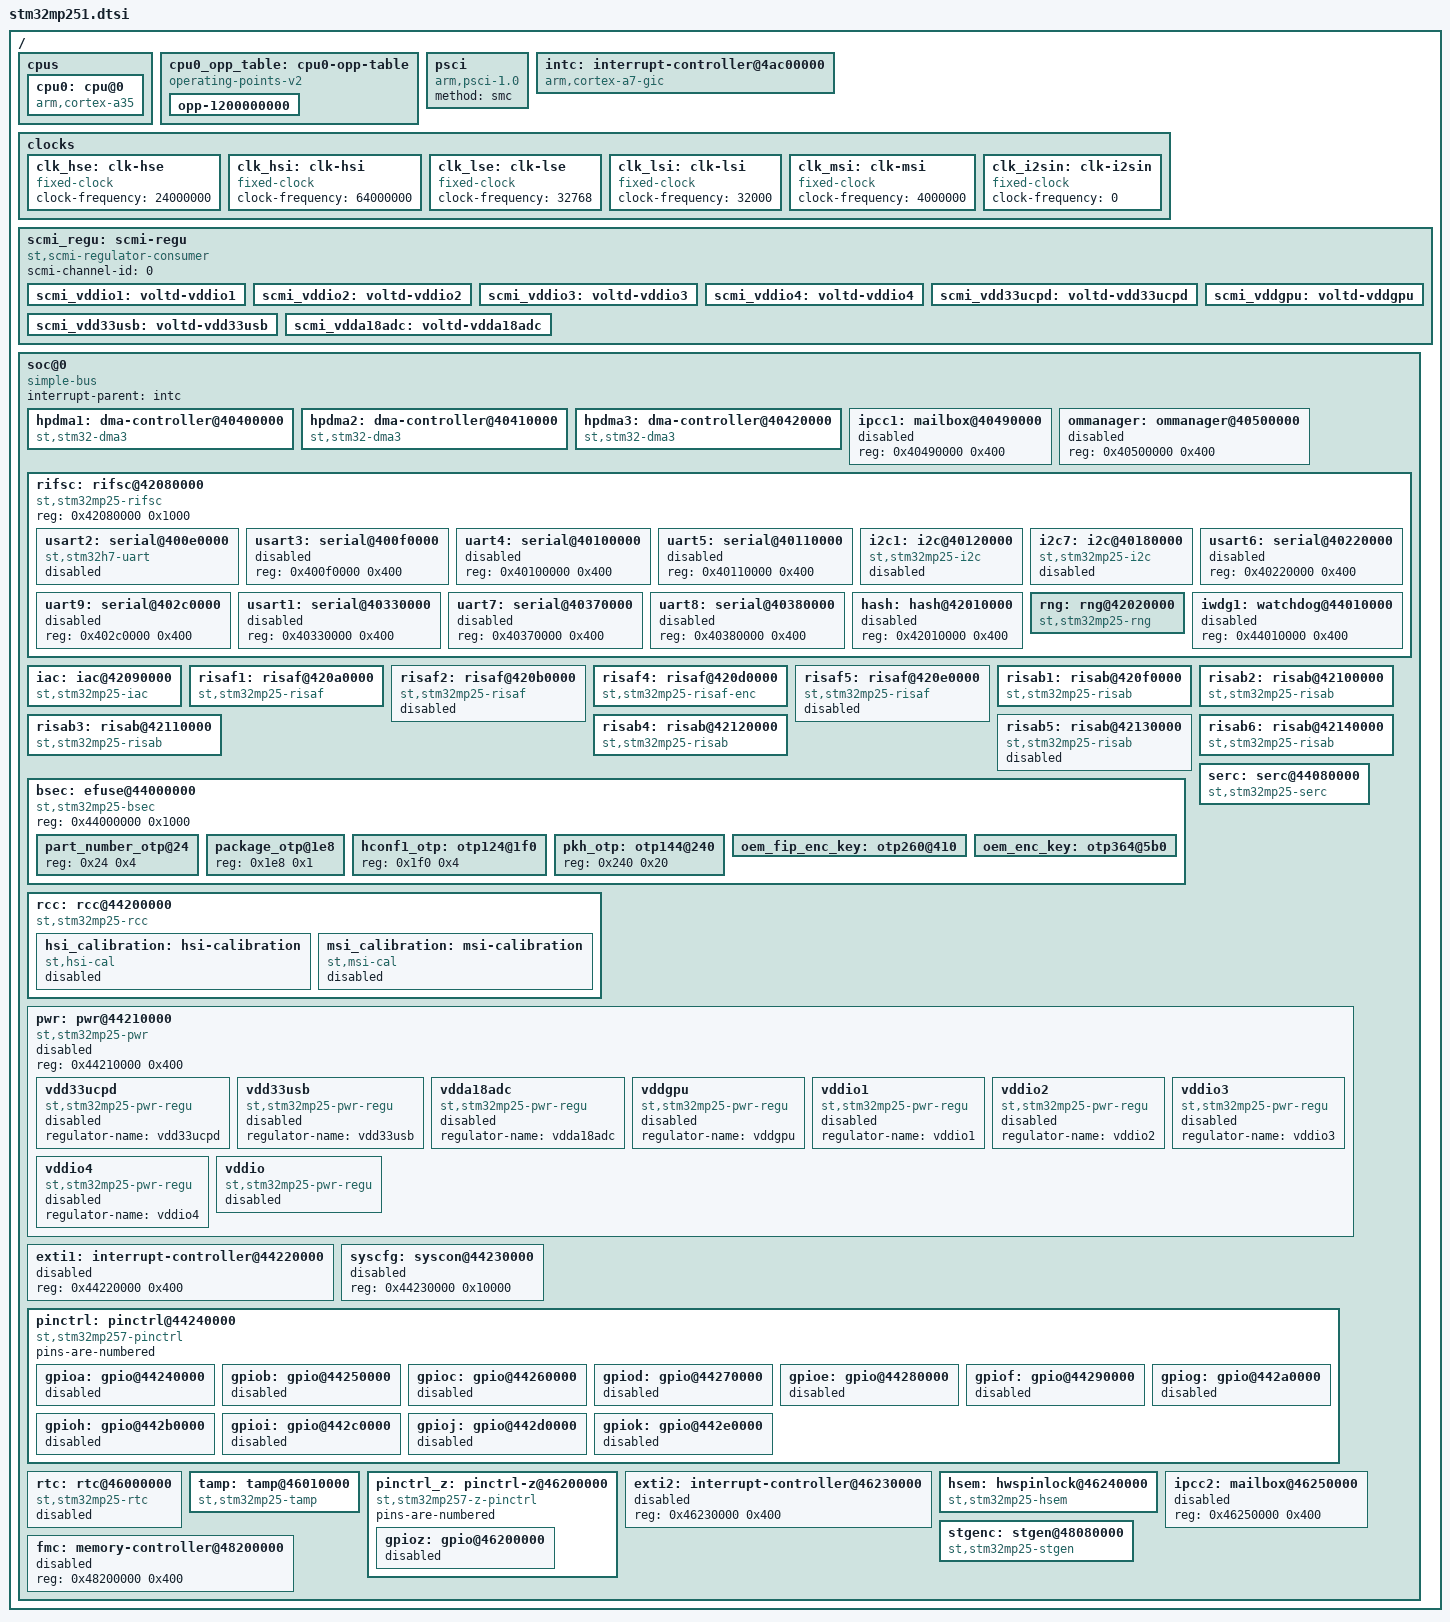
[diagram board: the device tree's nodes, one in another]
// SPDX-License-Identifier: (GPL-2.0+ OR BSD-3-Clause)
/*
 * Copyright (C) STMicroelectronics 2021 - All Rights Reserved
 * Author: Alexandre Torgue <alexandre.torgue@foss.st.com> for STMicroelectronics.
 */

#include <dt-bindings/interrupt-controller/arm-gic.h>
#include <dt-bindings/clock/stm32mp25-clks.h>
#include <dt-bindings/regulator/st,stm32mp25-regulator.h>
#include <dt-bindings/reset/stm32mp25-resets.h>

/ {
	#address-cells = <2>;
	#size-cells = <2>;

	cpus {
		#address-cells = <1>;
		#size-cells = <0>;

		cpu0: cpu@0 {
			compatible = "arm,cortex-a35";
			device_type = "cpu";
			reg = <0>;
			enable-method = "psci";
			operating-points-v2 = <&cpu0_opp_table>;
			clocks = <&rcc CK_CPU1>;
		};
	};

	cpu0_opp_table: cpu0-opp-table {
		compatible = "operating-points-v2";

		opp-1200000000 {
			opp-hz = /bits/ 64 <1200000000>;
			opp-microvolt = <800000>;
			opp-supported-hw = <0x1>;
			st,opp-default;
		};
	};

	psci {
		compatible = "arm,psci-1.0";
		method = "smc";
	};

	intc: interrupt-controller@4ac00000 {
		compatible = "arm,cortex-a7-gic";
		#interrupt-cells = <3>;
		interrupt-controller;
		reg = <0x0 0x4ac10000 0x0 0x1000>,
		      <0x0 0x4ac20000 0x0 0x2000>,
		      <0x0 0x4ac40000 0x0 0x2000>,
		      <0x0 0x4ac60000 0x0 0x2000>;
		#address-cells = <1>;
	};

	clocks {
		clk_hse: clk-hse {
			#clock-cells = <0>;
			compatible = "fixed-clock";
			clock-frequency = <24000000>;
		};

		clk_hsi: clk-hsi {
			#clock-cells = <0>;
			compatible = "fixed-clock";
			clock-frequency = <64000000>;
		};

		clk_lse: clk-lse {
			#clock-cells = <0>;
			compatible = "fixed-clock";
			clock-frequency = <32768>;
		};

		clk_lsi: clk-lsi {
			#clock-cells = <0>;
			compatible = "fixed-clock";
			clock-frequency = <32000>;
		};

		clk_msi: clk-msi {
			#clock-cells = <0>;
			compatible = "fixed-clock";
			clock-frequency = <4000000>;
		};

		clk_i2sin: clk-i2sin {
			#clock-cells = <0>;
			compatible = "fixed-clock";
			clock-frequency = <0>;
		};
	};

	scmi_regu: scmi-regu {
		compatible = "st,scmi-regulator-consumer";
		#address-cells = <1>;
		#size-cells = <0>;

		scmi-channel-id = <0>;

		scmi_vddio1: voltd-vddio1 {
			reg = <VOLTD_SCMI_VDDIO1>;
			voltd-supply = <&vddio1>;
		};
		scmi_vddio2: voltd-vddio2 {
			reg = <VOLTD_SCMI_VDDIO2>;
			voltd-supply = <&vddio2>;
		};
		scmi_vddio3: voltd-vddio3 {
			reg = <VOLTD_SCMI_VDDIO3>;
			voltd-supply = <&vddio3>;
		};
		scmi_vddio4: voltd-vddio4 {
			reg = <VOLTD_SCMI_VDDIO4>;
			voltd-supply = <&vddio4>;
		};
		scmi_vdd33ucpd: voltd-vdd33ucpd {
			reg = <VOLTD_SCMI_UCPD>;
			voltd-supply = <&vdd33ucpd>;
		};
		scmi_vdd33usb: voltd-vdd33usb {
			reg = <VOLTD_SCMI_USB33>;
			voltd-supply = <&vdd33usb>;
		};
		scmi_vdda18adc: voltd-vdda18adc {
			reg = <VOLTD_SCMI_ADC>;
			voltd-supply = <&vdda18adc>;
		};
		scmi_vddgpu: voltd-vddgpu {
			reg = <VOLTD_SCMI_GPU>;
			voltd-supply = <&vddgpu>;
		};
	};

	soc@0 {
		compatible = "simple-bus";
		#address-cells = <1>;
		#size-cells = <1>;
		interrupt-parent = <&intc>;
		ranges = <0x0 0x0 0x0 0x80000000>;

		hpdma1: dma-controller@40400000 {
			compatible = "st,stm32-dma3";
			reg = <0x40400000 0x1000>;
			clocks = <&rcc CK_BUS_HPDMA1>;
			resets = <&rcc HPDMA1_R>;
			#dma-cells = <4>;
		};

		hpdma2: dma-controller@40410000 {
			compatible = "st,stm32-dma3";
			reg = <0x40410000 0x1000>;
			clocks = <&rcc CK_BUS_HPDMA2>;
			resets = <&rcc HPDMA2_R>;
			#dma-cells = <4>;
		};

		hpdma3: dma-controller@40420000 {
			compatible = "st,stm32-dma3";
			reg = <0x40420000 0x1000>;
			clocks = <&rcc CK_BUS_HPDMA3>;
			resets = <&rcc HPDMA3_R>;
			#dma-cells = <4>;
		};

		ipcc1: mailbox@40490000 {
			reg = <0x40490000 0x400>;
			status = "disabled";
		};

		ommanager: ommanager@40500000 {
			reg = <0x40500000 0x400>;
			status = "disabled";
		};

		rifsc: rifsc@42080000 {
			compatible = "st,stm32mp25-rifsc";
			reg = <0x42080000 0x1000>;
			#address-cells = <1>;
			#size-cells = <1>;

			usart2: serial@400e0000 {
				compatible = "st,stm32h7-uart";
				reg = <0x400e0000 0x400>;
				interrupts = <GIC_SPI 115 IRQ_TYPE_LEVEL_HIGH>;
				clocks = <&rcc CK_KER_USART2>;
				status = "disabled";
			};

			usart3: serial@400f0000 {
				reg = <0x400f0000 0x400>;
				status = "disabled";
			};

			uart4: serial@40100000 {
				reg = <0x40100000 0x400>;
				status = "disabled";
			};

			uart5: serial@40110000 {
				reg = <0x40110000 0x400>;
				status = "disabled";
			};

			i2c1: i2c@40120000 {
				compatible = "st,stm32mp25-i2c";
				reg = <0x40120000 0x400>;
				clocks = <&rcc CK_KER_I2C1>;
				resets = <&rcc I2C1_R>;
				#address-cells = <1>;
				#size-cells = <0>;
				i2c-analog-filter;
				status = "disabled";
			};

			i2c7: i2c@40180000 {
				compatible = "st,stm32mp25-i2c";
				reg = <0x40180000 0x400>;
				clocks = <&rcc CK_KER_I2C7>;
				resets = <&rcc I2C7_R>;
				#address-cells = <1>;
				#size-cells = <0>;
				i2c-analog-filter;
				status = "disabled";
			};

			usart6: serial@40220000 {
				reg = <0x40220000 0x400>;
				status = "disabled";
			};

			uart9: serial@402c0000 {
				reg = <0x402c0000 0x400>;
				status = "disabled";
			};

			usart1: serial@40330000 {
				reg = <0x40330000 0x400>;
				status = "disabled";
			};

			uart7: serial@40370000 {
				reg = <0x40370000 0x400>;
				status = "disabled";
			};

			uart8: serial@40380000 {
				reg = <0x40380000 0x400>;
				status = "disabled";
			};

			hash: hash@42010000  {
				reg = <0x42010000  0x400>;
				status = "disabled";
			};

			rng: rng@42020000 {
				compatible = "st,stm32mp25-rng";
				reg = <0x42020000 0x400>;
				clocks = <&rcc CK_BUS_RNG>;
				resets = <&rcc RNG_R>;
			};

			iwdg1: watchdog@44010000 {
				reg = <0x44010000 0x400>;
				status = "disabled";
			};
		};

		iac: iac@42090000 {
			compatible = "st,stm32mp25-iac";
			reg = <0x42090000 0x400>;
			interrupts = <GIC_SPI 246 IRQ_TYPE_LEVEL_HIGH>;
		};

		risaf1: risaf@420a0000 {
			compatible = "st,stm32mp25-risaf";
			reg = <0x420a0000 0x1000>;
			clocks = <&rcc CK_BUS_BKPSRAM>;
			st,mem-map = <0x42000000 0x2000>;
		};

		risaf2: risaf@420b0000 {
			compatible = "st,stm32mp25-risaf";
			reg = <0x420b0000 0x1000>;
			clocks = <&rcc CK_KER_OSPI1>;
			st,mem-map = <0x60000000 0x10000000>;
			status = "disabled";
		};

		risaf4: risaf@420d0000 {
			compatible = "st,stm32mp25-risaf-enc";
			reg = <0x420d0000 0x1000>;
			clocks = <&rcc CK_BUS_RISAF4>;
			st,mem-map = <0x80000000 0x80000000>;
		};

		risaf5: risaf@420e0000 {
			compatible = "st,stm32mp25-risaf";
			reg = <0x420e0000 0x1000>;
			clocks = <&rcc CK_BUS_PCIE>;
			st,mem-map = <0x10000000 0x10000000>;
			status = "disabled";
		};

		risab1: risab@420f0000 {
			compatible = "st,stm32mp25-risab";
			reg = <0x420f0000 0x1000>;
			clocks = <&rcc CK_ICN_LS_MCU>;
			st,mem-map = <0xa000000 0x20000>;
		};

		risab2: risab@42100000 {
			compatible = "st,stm32mp25-risab";
			reg = <0x42100000 0x1000>;
			clocks = <&rcc CK_ICN_LS_MCU>;
			st,mem-map = <0xa020000 0x20000>;
		};

		risab3: risab@42110000 {
			compatible = "st,stm32mp25-risab";
			reg = <0x42110000 0x1000>;
			clocks = <&rcc CK_ICN_LS_MCU>;
			st,mem-map = <0xa040000 0x20000>;
		};

		risab4: risab@42120000 {
			compatible = "st,stm32mp25-risab";
			reg = <0x42120000 0x1000>;
			clocks = <&rcc CK_ICN_LS_MCU>;
			st,mem-map = <0xa060000 0x20000>;
		};

		risab5: risab@42130000 {
			compatible = "st,stm32mp25-risab";
			reg = <0x42130000 0x1000>;
			clocks = <&rcc CK_ICN_LS_MCU>;
			st,mem-map = <0xa080000 0x20000>;
			status = "disabled";
		};

		risab6: risab@42140000 {
			compatible = "st,stm32mp25-risab";
			reg = <0x42140000 0x1000>;
			clocks = <&rcc CK_ICN_LS_MCU>;
			st,mem-map = <0xa0a0000 0x20000>;
		};

		bsec: efuse@44000000 {
			compatible = "st,stm32mp25-bsec";
			reg = <0x44000000 0x1000>;
			#address-cells = <1>;
			#size-cells = <1>;

			part_number_otp@24 {
				reg = <0x24 0x4>;
			};

			package_otp@1e8 {
				reg = <0x1e8 0x1>;
			};

			hconf1_otp: otp124@1f0 {
				reg = <0x1f0 0x4>;
			};

			pkh_otp: otp144@240 {
				reg = <0x240 0x20>;
			};

			oem_fip_enc_key: otp260@410 {
				reg = <0x410 0x20>;
				st,non-secure-otp-provisioning;
			};

			oem_enc_key: otp364@5b0 {
				reg = <0x5b0 0x10>;
				st,non-secure-otp-provisioning;
			};
		};

		serc: serc@44080000 {
			compatible = "st,stm32mp25-serc";
			reg = <0x44080000 0x1000>;
			interrupts = <GIC_SPI 240 IRQ_TYPE_LEVEL_HIGH>;
			clocks = <&rcc CK_BUS_SERC>;
		};

		rcc: rcc@44200000 {
			compatible = "st,stm32mp25-rcc", "syscon";
			reg = <0x44200000 0x10000>;
			interrupts = <GIC_SPI 259 IRQ_TYPE_LEVEL_HIGH>;

			#clock-cells = <1>;
			#reset-cells = <1>;
			clocks = <&clk_hse>, <&clk_hsi>, <&clk_lse>,
				 <&clk_lsi>, <&clk_msi>, <&clk_i2sin>;
			clock-names = "clk-hse", "clk-hsi", "clk-lse",
				      "clk-lsi", "clk-msi", "clk-i2sin";

			hsi_calibration: hsi-calibration {
				compatible = "st,hsi-cal";
				st,cal_hsi_dev = <31>;
				st,cal_hsi_ref = <1953>;
				status = "disabled";
			};

			msi_calibration: msi-calibration {
				compatible = "st,msi-cal";
				status = "disabled";
			};
		};

		pwr: pwr@44210000 {
			compatible = "st,stm32mp25-pwr";
			reg = <0x44210000 0x400>;
			status = "disabled";

			vdd33ucpd: vdd33ucpd {
				compatible = "st,stm32mp25-pwr-regu";
				regulator-name = "vdd33ucpd";
				status = "disabled";
			};

			vdd33usb: vdd33usb {
				compatible = "st,stm32mp25-pwr-regu";
				regulator-name = "vdd33usb";
				status = "disabled";
			};

			vdda18adc: vdda18adc {
				compatible = "st,stm32mp25-pwr-regu";
				regulator-name = "vdda18adc";
				status = "disabled";
			};

			vddgpu: vddgpu {
				compatible = "st,stm32mp25-pwr-regu";
				regulator-name = "vddgpu";
				status = "disabled";
			};

			vddio1: vddio1 {
				compatible = "st,stm32mp25-pwr-regu";
				regulator-name = "vddio1";
				status = "disabled";
			};

			vddio2: vddio2 {
				compatible = "st,stm32mp25-pwr-regu";
				regulator-name = "vddio2";
				status = "disabled";
			};

			vddio3: vddio3 {
				compatible = "st,stm32mp25-pwr-regu";
				regulator-name = "vddio3";
				status = "disabled";
			};

			vddio4: vddio4 {
				compatible = "st,stm32mp25-pwr-regu";
				regulator-name = "vddio4";
				status = "disabled";
			};

			vddio: vddio {
				compatible = "st,stm32mp25-pwr-regu";
				regulator-name = "vddio";
				regulator-always-on;
				status = "disabled";
			};
		};

		exti1: interrupt-controller@44220000 {
			reg = <0x44220000 0x400>;
			status = "disabled";
		};

		syscfg: syscon@44230000 {
			reg = <0x44230000 0x10000>;
			status = "disabled";
		};

		pinctrl: pinctrl@44240000 {
			#address-cells = <1>;
			#size-cells = <1>;
			compatible = "st,stm32mp257-pinctrl";
			ranges = <0 0x44240000 0xa0400>;
			pins-are-numbered;

			gpioa: gpio@44240000 {
				gpio-controller;
				#gpio-cells = <2>;
				interrupt-controller;
				#interrupt-cells = <2>;
				reg = <0x0 0x400>;
				clocks = <&rcc CK_BUS_GPIOA>;
				st,bank-name = "GPIOA";
				status = "disabled";
			};

			gpiob: gpio@44250000 {
				gpio-controller;
				#gpio-cells = <2>;
				interrupt-controller;
				#interrupt-cells = <2>;
				reg = <0x10000 0x400>;
				clocks = <&rcc CK_BUS_GPIOB>;
				st,bank-name = "GPIOB";
				status = "disabled";
			};

			gpioc: gpio@44260000 {
				gpio-controller;
				#gpio-cells = <2>;
				interrupt-controller;
				#interrupt-cells = <2>;
				reg = <0x20000 0x400>;
				clocks = <&rcc CK_BUS_GPIOC>;
				st,bank-name = "GPIOC";
				status = "disabled";
			};

			gpiod: gpio@44270000 {
				gpio-controller;
				#gpio-cells = <2>;
				interrupt-controller;
				#interrupt-cells = <2>;
				reg = <0x30000 0x400>;
				clocks = <&rcc CK_BUS_GPIOD>;
				st,bank-name = "GPIOD";
				status = "disabled";
			};

			gpioe: gpio@44280000 {
				gpio-controller;
				#gpio-cells = <2>;
				interrupt-controller;
				#interrupt-cells = <2>;
				reg = <0x40000 0x400>;
				clocks = <&rcc CK_BUS_GPIOE>;
				st,bank-name = "GPIOE";
				status = "disabled";
			};

			gpiof: gpio@44290000 {
				gpio-controller;
				#gpio-cells = <2>;
				interrupt-controller;
				#interrupt-cells = <2>;
				reg = <0x50000 0x400>;
				clocks = <&rcc CK_BUS_GPIOF>;
				st,bank-name = "GPIOF";
				status = "disabled";
			};

			gpiog: gpio@442a0000 {
				gpio-controller;
				#gpio-cells = <2>;
				interrupt-controller;
				#interrupt-cells = <2>;
				reg = <0x60000 0x400>;
				clocks = <&rcc CK_BUS_GPIOG>;
				st,bank-name = "GPIOG";
				status = "disabled";
			};

			gpioh: gpio@442b0000 {
				gpio-controller;
				#gpio-cells = <2>;
				interrupt-controller;
				#interrupt-cells = <2>;
				reg = <0x70000 0x400>;
				clocks = <&rcc CK_BUS_GPIOH>;
				st,bank-name = "GPIOH";
				status = "disabled";
			};

			gpioi: gpio@442c0000 {
				gpio-controller;
				#gpio-cells = <2>;
				interrupt-controller;
				#interrupt-cells = <2>;
				reg = <0x80000 0x400>;
				clocks = <&rcc CK_BUS_GPIOI>;
				st,bank-name = "GPIOI";
				status = "disabled";
			};

			gpioj: gpio@442d0000 {
				gpio-controller;
				#gpio-cells = <2>;
				interrupt-controller;
				#interrupt-cells = <2>;
				reg = <0x90000 0x400>;
				clocks = <&rcc CK_BUS_GPIOJ>;
				st,bank-name = "GPIOJ";
				status = "disabled";
			};

			gpiok: gpio@442e0000 {
				gpio-controller;
				#gpio-cells = <2>;
				interrupt-controller;
				#interrupt-cells = <2>;
				reg = <0xa0000 0x400>;
				clocks = <&rcc CK_BUS_GPIOK>;
				st,bank-name = "GPIOK";
				status = "disabled";
			};
		};

		rtc: rtc@46000000 {
			compatible = "st,stm32mp25-rtc";
			reg = <0x46000000 0x400>;
			clocks = <&rcc CK_BUS_RTC>, <&rcc RTC_CK>;
			clock-names = "pclk", "rtc_ck";
			interrupts = <GIC_SPI 15 IRQ_TYPE_LEVEL_HIGH>;
			status = "disabled";
		};

		tamp: tamp@46010000 {
			compatible = "st,stm32mp25-tamp";
			reg = <0x46010000 0x400>;
			clocks = <&rcc CK_BUS_RTC>;
			interrupts = <GIC_SPI 14 IRQ_TYPE_LEVEL_HIGH>;
		};

		pinctrl_z: pinctrl-z@46200000 {
			#address-cells = <1>;
			#size-cells = <1>;
			compatible = "st,stm32mp257-z-pinctrl";
			ranges = <0 0x46200000 0x400>;
			pins-are-numbered;

			gpioz: gpio@46200000 {
				gpio-controller;
				#gpio-cells = <2>;
				interrupt-controller;
				#interrupt-cells = <2>;
				reg = <0 0x400>;
				clocks = <&rcc CK_BUS_GPIOZ>;
				st,bank-name = "GPIOZ";
				st,bank-ioport = <11>;
				status = "disabled";
			};
		};

		exti2: interrupt-controller@46230000 {
			reg = <0x46230000 0x400>;
			status = "disabled";
		};

		hsem: hwspinlock@46240000 {
			compatible = "st,stm32mp25-hsem";
			reg = <0x46240000 0x400>;
			interrupts = <GIC_SPI 200 IRQ_TYPE_LEVEL_HIGH>;
			clocks = <&rcc CK_BUS_HSEM>;
		};

		ipcc2: mailbox@46250000 {
			reg = <0x46250000 0x400>;
			status = "disabled";
		};

		stgenc: stgen@48080000 {
			compatible = "st,stm32mp25-stgen";
			reg = <0x48080000 0x1000>;
			clocks = <&rcc CK_BUS_STGEN>, <&rcc CK_KER_STGEN>;
			clock-names = "bus", "tsgen_clk";
			st,tsgen-clk-source = <&rcc HSE_CK>;
		};

		fmc: memory-controller@48200000 {
			reg = <0x48200000 0x400>;
			status = "disabled";
		};
	};
};
